# nrf52 register map
Vendor: Nordic Semiconductor; Series: nrf52; File version: 1
CPU: CM4 r0p1, little endian, MPU, FPU, 3 interrupt priority bits
Registers are 32-bit, read-write, reset 0x0 unless marked. A register's access mark holds for its fields unless they carry their own. Offsets are from the block's base; [hi:lo] are bit positions; 'fields as' and 'values as' point back to an identical list.

## RNG — Random Number Generator
Base 0x4000D000
0x00 TASKS_START wo — Task starting the random number generator
0x04 TASKS_STOP wo — Task stopping the random number generator
0x100 EVENTS_VALRDY — Event being generated for every new random number written to the VALUE register
0x200 SHORTS — Shortcut register
  [0] VALRDY_STOP — Shortcut between VALRDY event and STOP task
    0=Disabled (Disable shortcut); 1=Enabled (Enable shortcut)
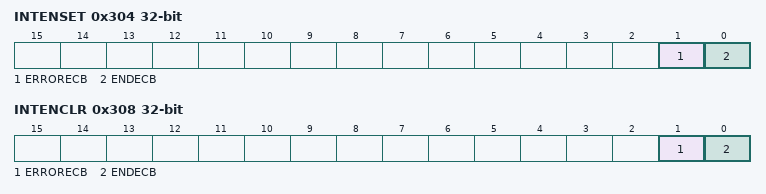
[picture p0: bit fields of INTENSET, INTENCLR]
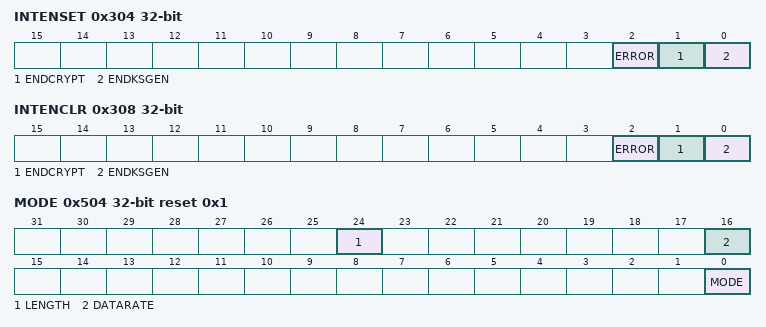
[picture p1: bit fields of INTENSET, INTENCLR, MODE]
0x304 INTENSET — Enable interrupt
  [0] VALRDY — Write '1' to Enable interrupt for VALRDY event
    on read: 0=Disabled (Read: Disabled); 1=Enabled (Read: Enabled) | on write: 1=Set (Enable)
0x308 INTENCLR — Disable interrupt
  [0] VALRDY — Write '1' to Disable interrupt for VALRDY event
    on read: 0=Disabled (Read: Disabled); 1=Enabled (Read: Enabled) | on write: 1=Clear (Disable)
0x504 CONFIG — Configuration register
  [0] DERCEN — Bias correction
    0=Disabled; 1=Enabled
0x508 VALUE ro — Output random number
  [7:0] VALUE — Generated random number

## ECB — AES ECB Mode Encryption
Base 0x4000E000
0x00 TASKS_STARTECB wo — Start ECB block encrypt
0x04 TASKS_STOPECB wo — Abort a possible executing ECB operation
0x100 EVENTS_ENDECB — ECB block encrypt complete
0x104 EVENTS_ERRORECB — ECB block encrypt aborted because of a STOPECB task or due to an error
0x304 INTENSET — Enable interrupt
  [1] ERRORECB — Write '1' to Enable interrupt for ERRORECB event
    on read: 0=Disabled (Read: Disabled); 1=Enabled (Read: Enabled) | on write: 1=Set (Enable)
  [0] ENDECB — Write '1' to Enable interrupt for ENDECB event
    values as ERRORECB
0x308 INTENCLR — Disable interrupt
  [1] ERRORECB — Write '1' to Disable interrupt for ERRORECB event
    on read: 0=Disabled (Read: Disabled); 1=Enabled (Read: Enabled) | on write: 1=Clear (Disable)
  [0] ENDECB — Write '1' to Disable interrupt for ENDECB event
    values as ERRORECB
0x504 ECBDATAPTR — ECB block encrypt memory pointers
  [31:0] ECBDATAPTR — Pointer to the ECB data structure (see Table 1 ECB data structure overview)

## CCM — AES CCM Mode Encryption
Base 0x4000F000
0x00 TASKS_KSGEN wo — Start generation of key-stream. This operation will stop by itself when completed.
0x04 TASKS_CRYPT wo — Start encryption/decryption. This operation will stop by itself when completed.
0x08 TASKS_STOP wo — Stop encryption/decryption
0x100 EVENTS_ENDKSGEN — Key-stream generation complete
0x104 EVENTS_ENDCRYPT — Encrypt/decrypt complete
0x108 EVENTS_ERROR — CCM error event
0x200 SHORTS — Shortcut register
  [0] ENDKSGEN_CRYPT — Shortcut between ENDKSGEN event and CRYPT task
    0=Disabled (Disable shortcut); 1=Enabled (Enable shortcut)
0x304 INTENSET — Enable interrupt
  [all] fields
    on read: 0=Disabled (Read: Disabled); 1=Enabled (Read: Enabled) | on write: 1=Set (Enable)
  [2] ERROR — Write '1' to Enable interrupt for ERROR event
  [1] ENDCRYPT — Write '1' to Enable interrupt for ENDCRYPT event
  [0] ENDKSGEN — Write '1' to Enable interrupt for ENDKSGEN event
0x308 INTENCLR — Disable interrupt
  [all] fields
    on read: 0=Disabled (Read: Disabled); 1=Enabled (Read: Enabled) | on write: 1=Clear (Disable)
  [2] ERROR — Write '1' to Disable interrupt for ERROR event
  [1] ENDCRYPT — Write '1' to Disable interrupt for ENDCRYPT event
  [0] ENDKSGEN — Write '1' to Disable interrupt for ENDKSGEN event
0x400 MICSTATUS ro — MIC check result
  [0] MICSTATUS — The result of the MIC check performed during the previous decryption operation
    0=CheckFailed (MIC check failed); 1=CheckPassed (MIC check passed)
0x500 ENABLE
  [1:0] ENABLE — Enable or disable CCM
    0=Disabled; 2=Enabled
0x504 MODE reset 0x1 — Operation mode
  [24] LENGTH — Packet length configuration
    0=Default length. Effective length of LENGTH field is 5-bit; 1=Extended length. Effective length of LENGTH field is 8-bit
  [16] DATARATE — Data rate that the CCM shall run in synch with
    0=1Mbit (In synch with 1 Mbit data rate); 1=2Mbit (In synch with 2 Mbit data rate)
  [0] MODE — The mode of operation to be used
    0=Encryption (AES CCM packet encryption mode); 1=Decryption (AES CCM packet decryption mode)
0x508 CNFPTR — Pointer to data structure holding AES key and NONCE vector
  [31:0] CNFPTR — Pointer to the data structure holding the AES key and the CCM NONCE vector (see Table 1 CCM data structure overview)
0x50C INPTR — Input pointer
0x510 OUTPTR — Output pointer
0x514 SCRATCHPTR — Pointer to data area used for temporary storage
  [31:0] SCRATCHPTR — Pointer to a scratch data area used for temporary storage during key-stream generation, MIC generation and encryption/decryption.
